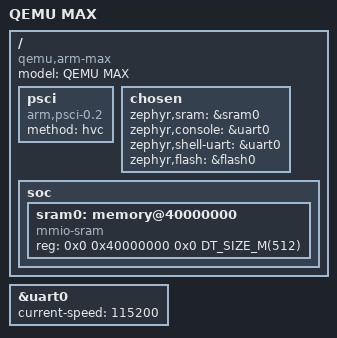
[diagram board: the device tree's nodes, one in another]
/*
 * Copyright 2024-2025 HNU-ESNL: Guoqi Xie, Chenglai Xiong, Xingyu Hu and etc.
 * Copyright 2024-2025 openEuler SIG-Zephyr
 *
 * SPDX-License-Identifier: Apache-2.0
 */

/dts-v1/;
#include <arm64/qemu/qemu-virt-max.dtsi>

/ {
	model = "QEMU MAX";
	compatible = "qemu,arm-max";

	psci {
		compatible = "arm,psci-0.2";
		method = "hvc";
	};

	chosen {
		zephyr,sram = &sram0;
		zephyr,console = &uart0;
		zephyr,shell-uart = &uart0;
		zephyr,flash = &flash0;
	};

	soc {
		sram0: memory@40000000 {
			compatible = "mmio-sram";
			reg = <0x0 0x40000000 0x0 DT_SIZE_M(512)>;
		};
	};

};

&uart0 {
	status = "okay";
	current-speed = <115200>;
};
